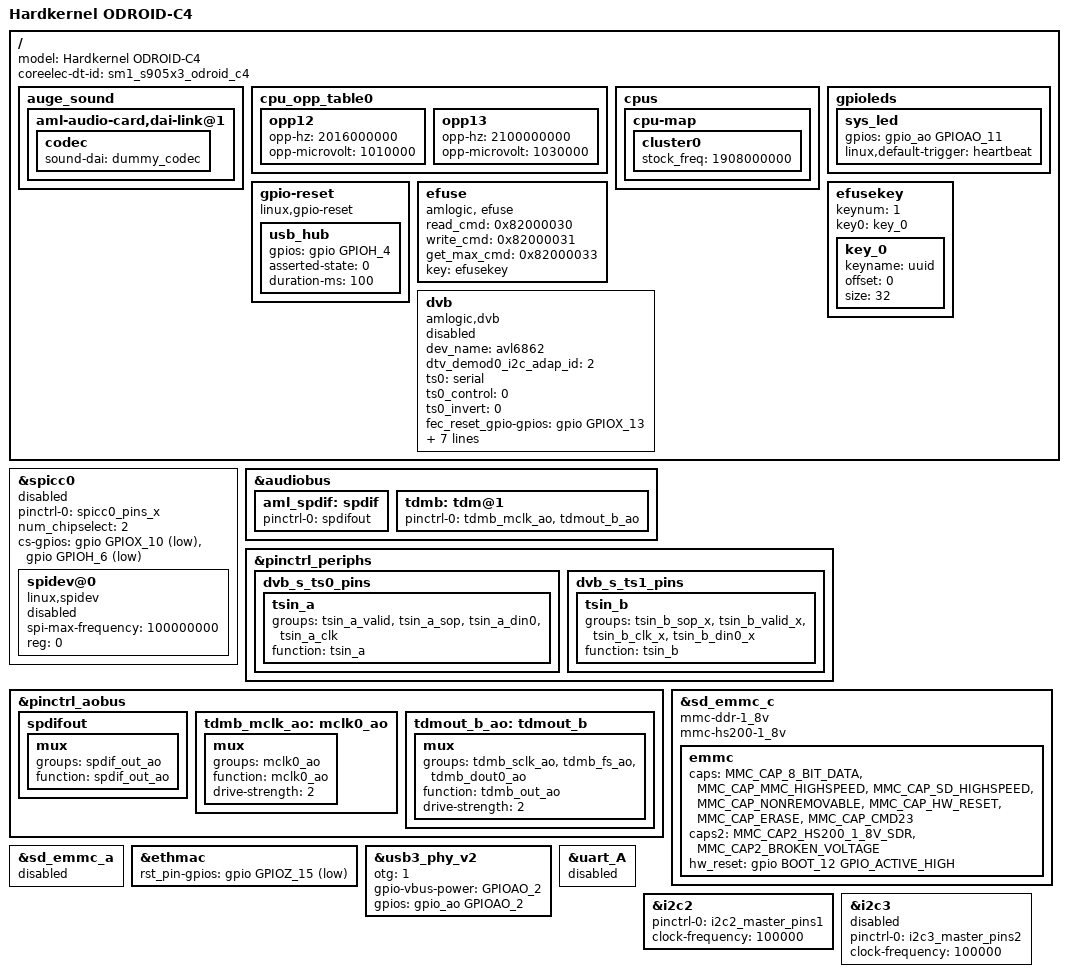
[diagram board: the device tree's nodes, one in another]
#include "sm1_s905x3_4g_1gbit.dts"

/{
	model = "Hardkernel ODROID-C4";
	/delete-property/ amlogic-dt-id;
	coreelec-dt-id = "sm1_s905x3_odroid_c4";

	/delete-node/ memory@00000000;
	/delete-node/ bt-dev;
	/delete-node/ wifi;
	/delete-node/ wifi_pwm_conf;
	/delete-node/ adc_keypad;
	/delete-node/ unifykey;

	/delete-node/ t9015;

	auge_sound {
		/delete-property/ avout_mute-gpios;
		aml-audio-card,dai-link@1 {
			codec {
				sound-dai = <&dummy_codec>;
			};
		};
	};

	cpu_opp_table0: cpu_opp_table0 {
		opp12 {
			opp-hz = /bits/ 64 <2016000000>;
			opp-microvolt = <1010000>;
		};
		opp13 {
			opp-hz = /bits/ 64 <2100000000>;
			opp-microvolt = <1030000>;
		};
	};

	cpus:cpus {
		cpu-map {
			cluster0:cluster0 {
				stock_freq = <1908000000>;
			};
		};
	};

	gpioleds {
		sys_led {
			gpios = <&gpio_ao GPIOAO_11 GPIO_ACTIVE_HIGH>;
			linux,default-trigger = "heartbeat";
		};
	};

	gpio-reset {
		compatible = "linux,gpio-reset";
		usb_hub {
			gpios = <&gpio GPIOH_4 GPIO_ACTIVE_HIGH>;
			asserted-state = <0>;
			duration-ms = <100>;
		};
	};

	efuse: efuse {
		compatible = "amlogic, efuse";
		read_cmd = <0x82000030>;
		write_cmd = <0x82000031>;
		get_max_cmd = <0x82000033>;
		key = <&efusekey>;
		status = "okay";
	};

	efusekey: efusekey {
		keynum = <1>;
		key0 = <&key_0>;

		key_0: key_0 {
			keyname = "uuid";
			offset = <0>;
			size = <32>;
		};
	};

	dvb {
		compatible = "amlogic,dvb";
		dev_name = "avl6862";
		status = "disabled";
		dtv_demod0_i2c_adap_id = <2>;
		ts0 = "serial";
		ts0_control = <0>;
		ts0_invert = <0>;
		fec_reset_gpio-gpios = <&gpio GPIOX_13 GPIO_ACTIVE_HIGH>;
		power_ctrl_gpio-gpios = <&gpio GPIOX_12 GPIO_ACTIVE_LOW>;
		pinctrl-names = "s_ts0", "s_ts1";
		pinctrl-0 = <&dvb_s_ts0_pins>;
		pinctrl-1 = <&dvb_s_ts1_pins>;
		interrupts = <GIC_SPI 23 IRQ_TYPE_EDGE_RISING>,
			     <GIC_SPI  5 IRQ_TYPE_EDGE_RISING>,
			     <GIC_SPI 19 IRQ_TYPE_EDGE_RISING>,
			     <GIC_SPI 25 IRQ_TYPE_EDGE_RISING>;
		interrupt-names = "demux0", "demux1", "asyncfifo0", "asyncfifo1";
	};
};

&spicc0 {
	status = "disabled";

	/*
	 40 Pin Header : MOSI(GPIOX.8->19 Pin), MISO(GPIOX.9->21 Pin),
			 SPI0_CLK(GPIOX.11->23 Pin)
			 SPI_CE0(GPIOX.2->22 Pin), SPI_CE1(GPIOX.10->24 Pin)
	*/
	pinctrl-names = "default","gpio_periphs";
	pinctrl-0 = <&spicc0_pins_x>;
	num_chipselect = <2>;

	cs-gpios = <&gpio GPIOX_10 GPIO_ACTIVE_LOW>,
		   <&gpio GPIOH_6 GPIO_ACTIVE_LOW>;

	spidev@0 {
		status = "disabled";

		compatible = "linux,spidev";
		/* spi default max clock 100Mhz */
		spi-max-frequency = <100000000>;
		reg = <0>;
	};
};

&audiobus {
	aml_spdif: spdif {
		pinctrl-names = "spdif_pins";
		pinctrl-0 = <&spdifout>;
	};

	tdmb: tdm@1 {
		pinctrl-0 = <&tdmb_mclk_ao &tdmout_b_ao>;
	};
};

&pinctrl_periphs {
	/delete-node/ spdifout;
	/delete-node/ spdifout_a_mute;

	dvb_s_ts0_pins: dvb_s_ts0_pins {
		tsin_a {
			groups ="tsin_a_valid",
				"tsin_a_sop",
				"tsin_a_din0",
				"tsin_a_clk";
			function = "tsin_a";
		};
	};

	dvb_s_ts1_pins: dvb_s_ts1_pins {
		tsin_b {
			groups = "tsin_b_sop_x",
			"tsin_b_valid_x",
			"tsin_b_clk_x",
			"tsin_b_din0_x";
			function = "tsin_b";
		};
	};
};

&pinctrl_aobus {
	spdifout: spdifout {
		mux {
			groups = "spdif_out_ao";
			function = "spdif_out_ao";
		};
	};

	tdmb_mclk_ao: mclk0_ao {
		mux { /* GPIOAO_9 */
			groups = "mclk0_ao";
			function = "mclk0_ao";
			drive-strength = <2>;
		};
	};

	tdmout_b_ao: tdmout_b {
		mux { /* GPIOAO_8, GPIOAO_7, GPIOAO_4 */
			groups = "tdmb_sclk_ao",
				"tdmb_fs_ao",
				"tdmb_dout0_ao";
			function = "tdmb_out_ao";
			drive-strength = <2>;
		};
	};
};

&sd_emmc_c {
	mmc-ddr-1_8v;
	mmc-hs200-1_8v;
	emmc {
		caps = "MMC_CAP_8_BIT_DATA",
			 "MMC_CAP_MMC_HIGHSPEED",
			 "MMC_CAP_SD_HIGHSPEED",
			 "MMC_CAP_NONREMOVABLE",
			 "MMC_CAP_HW_RESET",
			 "MMC_CAP_ERASE",
			 "MMC_CAP_CMD23";
		caps2 = "MMC_CAP2_HS200_1_8V_SDR",
			"MMC_CAP2_BROKEN_VOLTAGE";
		hw_reset = <&gpio BOOT_12 GPIO_ACTIVE_HIGH>;
	};
};

&sd_emmc_a {
	status = "disabled";
	/delete-node/ sdio;
};

&ethmac {
	rst_pin-gpios = <&gpio GPIOZ_15 GPIO_ACTIVE_LOW>;
};

&usb3_phy_v2 {
	otg = <1>;
	gpio-vbus-power = "GPIOAO_2";
	gpios = <&gpio_ao GPIOAO_2 GPIO_ACTIVE_HIGH>;
};

&uart_A {
	status = "disabled";
};

&i2c2 {
	status = "okay";
	pinctrl-names = "default";
	pinctrl-0 = <&i2c2_master_pins1>;
	clock-frequency = <100000>;
};

&i2c3 {
	status = "disabled";
	pinctrl-names = "default";
	pinctrl-0 = <&i2c3_master_pins2>;
	clock-frequency = <100000>;
};
